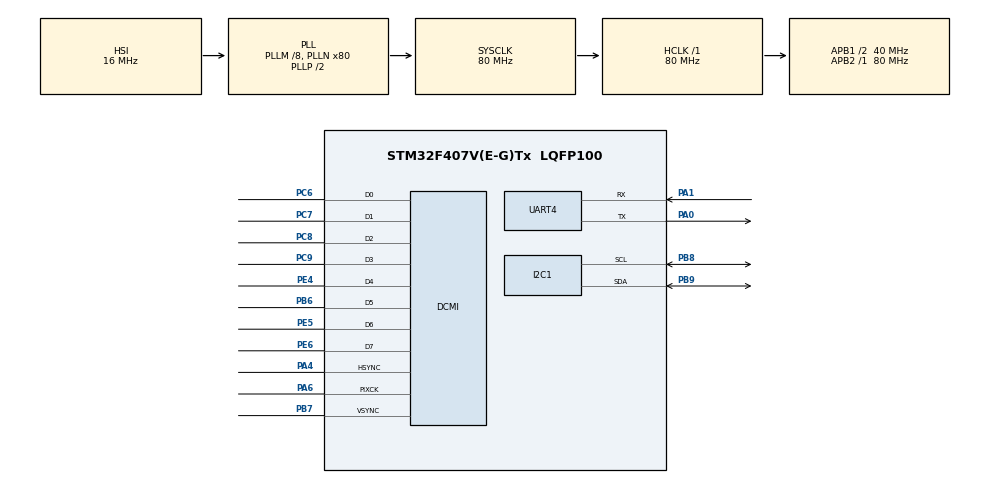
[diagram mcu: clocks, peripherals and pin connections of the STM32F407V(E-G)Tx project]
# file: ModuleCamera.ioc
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Dma.DCMI.0.Direction=DMA_PERIPH_TO_MEMORY
Dma.DCMI.0.FIFOMode=DMA_FIFOMODE_ENABLE
Dma.DCMI.0.FIFOThreshold=DMA_FIFO_THRESHOLD_FULL
Dma.DCMI.0.Instance=DMA2_Stream1
Dma.DCMI.0.MemBurst=DMA_MBURST_SINGLE
Dma.DCMI.0.MemDataAlignment=DMA_MDATAALIGN_WORD
Dma.DCMI.0.MemInc=DMA_MINC_ENABLE
Dma.DCMI.0.Mode=DMA_NORMAL
Dma.DCMI.0.PeriphBurst=DMA_PBURST_SINGLE
Dma.DCMI.0.PeriphDataAlignment=DMA_PDATAALIGN_WORD
Dma.DCMI.0.PeriphInc=DMA_PINC_DISABLE
Dma.DCMI.0.Priority=DMA_PRIORITY_LOW
Dma.Request0=DCMI
Dma.Request1=UART4_TX
Dma.UART4_TX.1.Direction=DMA_MEMORY_TO_PERIPH
Dma.UART4_TX.1.FIFOMode=DMA_FIFOMODE_DISABLE
Dma.UART4_TX.1.Instance=DMA1_Stream4
Dma.UART4_TX.1.MemDataAlignment=DMA_MDATAALIGN_BYTE
Dma.UART4_TX.1.MemInc=DMA_MINC_ENABLE
Dma.UART4_TX.1.Mode=DMA_NORMAL
Dma.UART4_TX.1.PeriphDataAlignment=DMA_PDATAALIGN_BYTE
Dma.UART4_TX.1.PeriphInc=DMA_PINC_DISABLE
Dma.UART4_TX.1.Priority=DMA_PRIORITY_LOW
Mcu.Family=STM32F4
Mcu.Name=STM32F407V(E-G)Tx
Mcu.Package=LQFP100
NVIC.DCMI_IRQn=true\:0\:0\:false\:false\:true\:true\:true
NVIC.DMA1_Stream4_IRQn=true\:0\:0\:false\:false\:true\:false\:true
NVIC.DMA2_Stream1_IRQn=true\:0\:0\:false\:false\:true\:false\:true
NVIC.PriorityGroup=NVIC_PRIORITYGROUP_4
PA0-WKUP.Mode=Asynchronous
PA0-WKUP.Signal=UART4_TX
PA1.Mode=Asynchronous
PA1.Signal=UART4_RX
PA4.Mode=Slave_8_bits_External_Synchro
PA4.Signal=DCMI_HSYNC
PA6.Mode=Slave_8_bits_External_Synchro
PA6.Signal=DCMI_PIXCK
PB6.Mode=Slave_8_bits_External_Synchro
PB6.Signal=DCMI_D5
PB7.Mode=Slave_8_bits_External_Synchro
PB7.Signal=DCMI_VSYNC
PB8.Mode=I2C
PB8.Signal=I2C1_SCL
PB9.Mode=I2C
PB9.Signal=I2C1_SDA
PC6.Mode=Slave_8_bits_External_Synchro
PC6.Signal=DCMI_D0
PC7.Mode=Slave_8_bits_External_Synchro
PC7.Signal=DCMI_D1
PC8.Mode=Slave_8_bits_External_Synchro
PC8.Signal=DCMI_D2
PC9.Mode=Slave_8_bits_External_Synchro
PC9.Signal=DCMI_D3
PE4.Mode=Slave_8_bits_External_Synchro
PE4.Signal=DCMI_D4
PE5.Mode=Slave_8_bits_External_Synchro
PE5.Signal=DCMI_D6
PE6.Mode=Slave_8_bits_External_Synchro
PE6.Signal=DCMI_D7
ProjectManager.HeapSize=0x200
ProjectManager.StackSize=0x400
ProjectManager.TargetToolchain=Makefile
RCC.48MHZClocksFreq_Value=40000000
RCC.AHBFreq_Value=80000000
RCC.APB1CLKDivider=RCC_HCLK_DIV2
RCC.APB1Freq_Value=40000000
RCC.APB1TimFreq_Value=80000000
RCC.APB2Freq_Value=80000000
RCC.APB2TimFreq_Value=80000000
RCC.CortexFreq_Value=80000000
RCC.HCLKFreq_Value=80000000
RCC.HSE_VALUE=25000000
RCC.HSI_VALUE=16000000
RCC.LSE_VALUE=32768
RCC.PLLM=8
RCC.PLLN=80
RCC.SYSCLKFreq_VALUE=80000000
RCC.SYSCLKSource=RCC_SYSCLKSOURCE_PLLCLK
RCC.VCOOutputFreq_Value=160000000
UART4.VirtualMode=Asynchronous
board=custom

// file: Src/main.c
/* USER CODE BEGIN Header */
/**
 ******************************************************************************
 * @file           : main.c
 * @brief          : Main program body
 ******************************************************************************
 * @attention
 *
 * <h2><center>&copy; Copyright (c) 2019 STMicroelectronics.
 * All rights reserved.</center></h2>
 *
 * This software component is licensed by ST under BSD 3-Clause license,
 * the "License"; You may not use this file except in compliance with the
 * License. You may obtain a copy of the License at:
 *                        opensource.org/licenses/BSD-3-Clause
 *
 ******************************************************************************
 */
/* USER CODE END Header */

#include "main.h"

/* USER CODE BEGIN Includes */
#include "user_main.h"
#include "var_interface.h"
/* USER CODE END Includes */

DCMI_HandleTypeDef hdcmi;
DMA_HandleTypeDef hdma_dcmi;

I2C_HandleTypeDef hi2c1;

UART_HandleTypeDef huart4;
DMA_HandleTypeDef hdma_uart4_tx;

/* USER CODE BEGIN PV */

uint8_t image_data[IMAGE_SIZE] = {0};
/* USER CODE END PV */

void SystemClock_Config(void);
static void MX_GPIO_Init(void);
static void MX_DMA_Init(void);
static void MX_DCMI_Init(void);
static void MX_I2C1_Init(void);
static void MX_UART4_Init(void);

int main(void)
{
  /* USER CODE BEGIN 1 */
  user_code1();

  /* USER CODE END 1 */

  /* MCU Configuration--------------------------------------------------------*/

  /* Reset of all peripherals, Initializes the Flash interface and the Systick. */
  HAL_Init();

  /* Configure the system clock */
  SystemClock_Config();

  /* Initialize all configured peripherals */
  MX_GPIO_Init();
  MX_DMA_Init();
  MX_DCMI_Init();
  MX_I2C1_Init();
  MX_UART4_Init();
  /* USER CODE BEGIN 2 */
  user_code2();

  /* USER CODE END 2 */

  /* Infinite loop */
  /* USER CODE BEGIN WHILE */
  while (1) {
    loop();
    /* USER CODE END WHILE */

    /* USER CODE BEGIN 3 */
  }
  user_code3();
  /* USER CODE END 3 */
}

void SystemClock_Config(void)
{
  RCC_OscInitTypeDef RCC_OscInitStruct = {0};
  RCC_ClkInitTypeDef RCC_ClkInitStruct = {0};

  /** Configure the main internal regulator output voltage
  */
  __HAL_RCC_PWR_CLK_ENABLE();
  __HAL_PWR_VOLTAGESCALING_CONFIG(PWR_REGULATOR_VOLTAGE_SCALE1);
  /** Initializes the CPU, AHB and APB busses clocks
  */
  RCC_OscInitStruct.OscillatorType = RCC_OSCILLATORTYPE_HSI;
  RCC_OscInitStruct.HSIState = RCC_HSI_ON;
  RCC_OscInitStruct.HSICalibrationValue = RCC_HSICALIBRATION_DEFAULT;
  RCC_OscInitStruct.PLL.PLLState = RCC_PLL_ON;
  RCC_OscInitStruct.PLL.PLLSource = RCC_PLLSOURCE_HSI;
  RCC_OscInitStruct.PLL.PLLM = 8;
  RCC_OscInitStruct.PLL.PLLN = 80;
  RCC_OscInitStruct.PLL.PLLP = RCC_PLLP_DIV2;
  RCC_OscInitStruct.PLL.PLLQ = 4;
  if (HAL_RCC_OscConfig(&RCC_OscInitStruct) != HAL_OK)
  {
    Error_Handler();
  }
  /** Initializes the CPU, AHB and APB busses clocks
  */
  RCC_ClkInitStruct.ClockType = RCC_CLOCKTYPE_HCLK|RCC_CLOCKTYPE_SYSCLK
                              |RCC_CLOCKTYPE_PCLK1|RCC_CLOCKTYPE_PCLK2;
  RCC_ClkInitStruct.SYSCLKSource = RCC_SYSCLKSOURCE_PLLCLK;
  RCC_ClkInitStruct.AHBCLKDivider = RCC_SYSCLK_DIV1;
  RCC_ClkInitStruct.APB1CLKDivider = RCC_HCLK_DIV2;
  RCC_ClkInitStruct.APB2CLKDivider = RCC_HCLK_DIV1;

  if (HAL_RCC_ClockConfig(&RCC_ClkInitStruct, FLASH_LATENCY_2) != HAL_OK)
  {
    Error_Handler();
  }
}

static void MX_DCMI_Init(void)
{

  hdcmi.Instance = DCMI;
  hdcmi.Init.SynchroMode = DCMI_SYNCHRO_HARDWARE;
  hdcmi.Init.PCKPolarity = DCMI_PCKPOLARITY_FALLING;
  hdcmi.Init.VSPolarity = DCMI_VSPOLARITY_LOW;
  hdcmi.Init.HSPolarity = DCMI_HSPOLARITY_LOW;
  hdcmi.Init.CaptureRate = DCMI_CR_ALL_FRAME;
  hdcmi.Init.ExtendedDataMode = DCMI_EXTEND_DATA_8B;
  hdcmi.Init.JPEGMode = DCMI_JPEG_DISABLE;
  if (HAL_DCMI_Init(&hdcmi) != HAL_OK)
  {
    Error_Handler();
  }

}

static void MX_I2C1_Init(void)
{

  hi2c1.Instance = I2C1;
  hi2c1.Init.ClockSpeed = 100000;
  hi2c1.Init.DutyCycle = I2C_DUTYCYCLE_2;
  hi2c1.Init.OwnAddress1 = 0;
  hi2c1.Init.AddressingMode = I2C_ADDRESSINGMODE_7BIT;
  hi2c1.Init.DualAddressMode = I2C_DUALADDRESS_DISABLE;
  hi2c1.Init.OwnAddress2 = 0;
  hi2c1.Init.GeneralCallMode = I2C_GENERALCALL_DISABLE;
  hi2c1.Init.NoStretchMode = I2C_NOSTRETCH_DISABLE;
  if (HAL_I2C_Init(&hi2c1) != HAL_OK)
  {
    Error_Handler();
  }

}

static void MX_UART4_Init(void)
{

  huart4.Instance = UART4;
  huart4.Init.BaudRate = 115200;
  huart4.Init.WordLength = UART_WORDLENGTH_8B;
  huart4.Init.StopBits = UART_STOPBITS_1;
  huart4.Init.Parity = UART_PARITY_NONE;
  huart4.Init.Mode = UART_MODE_TX_RX;
  huart4.Init.HwFlowCtl = UART_HWCONTROL_NONE;
  huart4.Init.OverSampling = UART_OVERSAMPLING_16;
  if (HAL_UART_Init(&huart4) != HAL_OK)
  {
    Error_Handler();
  }

}

static void MX_DMA_Init(void)
{

  /* DMA controller clock enable */
  __HAL_RCC_DMA2_CLK_ENABLE();
  __HAL_RCC_DMA1_CLK_ENABLE();

  /* DMA interrupt init */
  /* DMA1_Stream4_IRQn interrupt configuration */
  HAL_NVIC_SetPriority(DMA1_Stream4_IRQn, 0, 0);
  HAL_NVIC_EnableIRQ(DMA1_Stream4_IRQn);
  /* DMA2_Stream1_IRQn interrupt configuration */
  HAL_NVIC_SetPriority(DMA2_Stream1_IRQn, 0, 0);
  HAL_NVIC_EnableIRQ(DMA2_Stream1_IRQn);

}

static void MX_GPIO_Init(void)
{

  /* GPIO Ports Clock Enable */
  __HAL_RCC_GPIOE_CLK_ENABLE();
  __HAL_RCC_GPIOA_CLK_ENABLE();
  __HAL_RCC_GPIOC_CLK_ENABLE();
  __HAL_RCC_GPIOB_CLK_ENABLE();

}

void Error_Handler(void)
{
}

#ifdef  USE_FULL_ASSERT
/**
  * @brief  Reports the name of the source file and the source line number
  *         where the assert_param error has occurred.
  * @param  file: pointer to the source file name
  * @param  line: assert_param error line source number
  * @retval None
  */
void assert_failed(uint8_t *file, uint32_t line)
{
  /* USER CODE BEGIN 6 */
  /* User can add his own implementation to report the file name and line
     number,
     tex: printf("Wrong parameters value: file %s on line %d\r\n", file, line)
   */
  /* USER CODE END 6 */
}
#endif /* USE_FULL_ASSERT */

/************************ (C) COPYRIGHT STMicroelectronics *****END OF FILE****/
